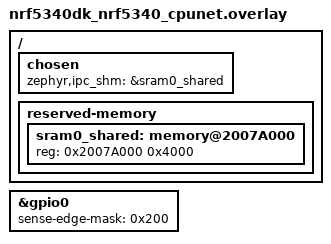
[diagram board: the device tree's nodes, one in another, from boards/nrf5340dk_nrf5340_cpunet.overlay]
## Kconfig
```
#
# Copyright (c) 2018 Nordic Semiconductor
#
# SPDX-License-Identifier: LicenseRef-BSD-5-Clause-Nordic
#

source "Kconfig.zephyr"

menu "Nordic UART BLE GATT service sample"

config BT_NUS_THREAD_STACK_SIZE
	int "Thread stack size"
	default 1024
	help
	  Stack size used in each of the two threads

config BT_NUS_UART_BUFFER_SIZE
	int "UART payload buffer element size"
	default 40
	help
	  Size of the payload buffer in each RX and TX FIFO element

config BT_NUS_SECURITY_ENABLED
	bool "Enable security"
	default y
	select BT_SMP
	help
	  "Enable BLE security for the UART service"

config BT_NUS_UART_RX_WAIT_TIME
	int "Timeout for UART RX complete event"
	default 50
	help
	  Wait for RX complete event time in milliseconds

endmenu

menu "nRF53 BLE custom"

config RPC_REMOTE_API
	bool "app core and net core communicate by remote API. that is, app core can call net core API, and net core can also call app core API"
	help
	  enable the RPC api mode
	
config RPC_SMP_BT
	bool "load DFU example over BLE SMP"
	help
		if yes, load DFU example over BLE SMP

endmenu	  
```

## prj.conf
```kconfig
#
# Copyright (c) 2018 Nordic Semiconductor
#
# SPDX-License-Identifier: LicenseRef-BSD-5-Clause-Nordic
#

## Open the config if you want to debug netcore ##
# CONFIG_NULL_POINTER_EXCEPTION_DETECTION_NONE=y

# Config logger
CONFIG_LOG=y
CONFIG_LOG_PRINTK=y
CONFIG_ASSERT=y
# CONFIG_LOG_BUFFER_SIZE=4096

# ## disable logging ##
# CONFIG_LOG=n
# CONFIG_USE_SEGGER_RTT=n
# CONFIG_SERIAL=n
# CONFIG_ASSERT=n
# CONFIG_PRINTK=n

# CONFIG_PRINTK=y
# CONFIG_SERIAL=y

# CONFIG_HEAP_MEM_POOL_SIZE=4096
# CONFIG_SYSTEM_WORKQUEUE_STACK_SIZE=4096

## nrf_rpc configurations ##
CONFIG_RPC_REMOTE_API=y
CONFIG_NRF_RPC=y
CONFIG_NRF_RPC_CBOR=y
CONFIG_NRF_RPC_THREAD_STACK_SIZE=4096

## Open the following config to run SMP OTA ##
CONFIG_RPC_SMP_BT=y
CONFIG_MCUMGR_SMP_BT_AUTHEN=n
# CONFIG_MCUMGR_SMP_REASSEMBLY_BT=y
# CONFIG_MCUMGR_SMP_BT_CONN_PARAM_CONTROL=y

## BT configurations ##
CONFIG_BT=y
CONFIG_BT_PERIPHERAL=y
CONFIG_BT_DEVICE_NAME="comprehensive_rpc"
#limited by RPMSG_BUFFER_SIZE
CONFIG_BT_L2CAP_TX_MTU=396
CONFIG_BT_BUF_ACL_RX_SIZE=400
CONFIG_BT_BUF_ACL_TX_SIZE=400
CONFIG_BT_CTLR_DATA_LENGTH_MAX=251
CONFIG_BT_PERIPHERAL_PREF_MIN_INT=6
CONFIG_BT_PERIPHERAL_PREF_MAX_INT=9
CONFIG_BT_GATT_DYNAMIC_DB=y
CONFIG_BT_RX_STACK_SIZE=4096

# Enable the NUS service
CONFIG_BT_NUS=y

## Enable bonding ##
# CONFIG_BT_SETTINGS=y
# CONFIG_BT_L2CAP_DYNAMIC_CHANNEL=y
# CONFIG_BT_SETTINGS_CCC_STORE_ON_WRITE=y
# CONFIG_BT_NUS_SECURITY_ENABLED=y
# CONFIG_BT_SMP_ALLOW_UNAUTH_OVERWRITE=y
# # CONFIG_BT_USE_DEBUG_KEYS=y
# # CONFIG_BT_STORE_DEBUG_KEYS=y

## Open the following config to run nrf_dfu OTA ##
# CONFIG_NRF_DFU_BT=y
# CONFIG_NRF_DFU_RPC_NET=y

## Enable bonding ##
CONFIG_BT_NUS_SECURITY_ENABLED=n
# CONFIG_BT_SETTINGS=y
# CONFIG_FLASH=y
# CONFIG_FLASH_PAGE_LAYOUT=y
# CONFIG_FLASH_MAP=y
# CONFIG_NVS=y
# # CONFIG_SETTINGS_NVS_SECTOR_COUNT=2
# CONFIG_PM_PARTITION_SIZE_SETTINGS_STORAGE=0x1000
# CONFIG_SETTINGS=y
# CONFIG_BT_SMP_ALLOW_UNAUTH_OVERWRITE=y
CONFIG_BT_LL_SW_SPLIT=y
```

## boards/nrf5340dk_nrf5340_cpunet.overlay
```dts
/delete-node/ &sram0_shared;

/ {
	chosen {
		/* shared memory reserved for the inter-processor communication */
		zephyr,ipc_shm = &sram0_shared;
	};

	reserved-memory {
		#address-cells = <1>;
		#size-cells = <1>;
		ranges;	
		sram0_shared: memory@2007A000 {
			/* SRAM allocated to shared memory */
			reg = <0x2007A000 0x4000>;
		};
	};
};

&gpio0 {
	/* button4 -> P0.9 sense for edge */
	sense-edge-mask = <0x200>;
};
```

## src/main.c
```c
/*
 * Copyright (c) 2018 Nordic Semiconductor ASA
 *
 * SPDX-License-Identifier: LicenseRef-BSD-5-Clause-Nordic
 */

/** @file
 *  @brief Nordic UART Bridge Service (NUS) sample
 */

#include <zephyr/types.h>
#include <zephyr/kernel.h>
#include <zephyr/drivers/uart.h>
#include <zephyr/device.h>
#include <soc.h>
#include <zephyr/bluetooth/bluetooth.h>
#include <zephyr/bluetooth/uuid.h>
#include <zephyr/bluetooth/gatt.h>
#include <zephyr/bluetooth/hci.h>
#include <bluetooth/services/nus.h>
#include <zephyr/settings/settings.h>
#include <stdio.h>
#include <zephyr/logging/log.h>
#include "rpc_net_api.h"
#include <zephyr/drivers/gpio.h>

#ifdef CONFIG_RPC_SMP_BT
#include "rpc_net_smp_bt.h"
#endif

#define LOG_MODULE_NAME main
LOG_MODULE_REGISTER(LOG_MODULE_NAME);

#define STACKSIZE CONFIG_BT_NUS_THREAD_STACK_SIZE
#define PRIORITY 7

#define DEVICE_NAME CONFIG_BT_DEVICE_NAME
#define DEVICE_NAME_LEN	(sizeof(DEVICE_NAME) - 1)

#define KEY_PASSKEY_ACCEPT DK_BTN1_MSK
#define KEY_PASSKEY_REJECT DK_BTN2_MSK


static K_SEM_DEFINE(ble_conn_ok, 0, 1);

struct bt_conn *current_conn;
// static struct bt_conn *auth_conn;

static const struct bt_data ad[] = {
	BT_DATA_BYTES(BT_DATA_FLAGS, (BT_LE_AD_GENERAL | BT_LE_AD_NO_BREDR)),
	BT_DATA(BT_DATA_NAME_COMPLETE, DEVICE_NAME, DEVICE_NAME_LEN),
};

/*
static const struct bt_data sd[] = {
	BT_DATA_BYTES(BT_DATA_UUID128_ALL, BT_UUID_NUS_VAL),
};
*/


K_SEM_DEFINE(sem_nus_op, 0, 1);

const struct device *gpio_dev;
#define EXT_INT_IO	9  //p0.09
#define EXT_INT_CONF	(GPIO_INPUT | GPIO_PULL_UP)
static struct gpio_callback ext_int_cb_data;

#ifdef CONFIG_BT_GATT_CLIENT
static struct bt_gatt_exchange_params exchange_params;

static void exchange_func(struct bt_conn *conn, uint8_t att_err,
			  struct bt_gatt_exchange_params *params)
{
	if (att_err)
	{
		LOG_ERR("MTU exchange failed");
	}
	else
	{
		LOG_INF("MTU updated to %d", bt_gatt_get_mtu(conn)); 
	}
	
}
#endif

static void connected(struct bt_conn *conn, uint8_t err)
{
	char addr[BT_ADDR_LE_STR_LEN];	

	if (err) {
		LOG_ERR("Connection failed (err %u)", err);
		return;
	}

	bt_addr_le_to_str(bt_conn_get_dst(conn), addr, sizeof(addr));
	LOG_INF("Connected %s", (addr));

	current_conn = bt_conn_ref(conn);

	k_sem_give(&ble_conn_ok);

#ifdef CONFIG_BT_NUS_SECURITY_ENABLED
	if (bt_conn_set_security(conn, BT_SECURITY_L2)) {
		printk("Failed to set security\n");
	}	
#endif

#ifdef CONFIG_RPC_REMOTE_API
	err = net2app_send_conn_status(1);
	if (err) {
		LOG_ERR("send connected err %d", err);
	}	
#endif

#ifdef CONFIG_BT_GATT_CLIENT		
	exchange_params.func = exchange_func;
	err = bt_gatt_exchange_mtu(conn, &exchange_params);
	if (err) {
		LOG_ERR("MTU exchange failed");
	} 		
#endif
	
}

static void disconnected(struct bt_conn *conn, uint8_t reason)
{
	char addr[BT_ADDR_LE_STR_LEN];

	bt_addr_le_to_str(bt_conn_get_dst(conn), addr, sizeof(addr));

	LOG_INF("Disconnected: %s (reason %u)", (addr), reason);

	if (current_conn) {
		bt_conn_unref(current_conn);
		current_conn = NULL;		
	}

#ifdef CONFIG_RPC_REMOTE_API
	int err = net2app_send_conn_status(0);
	if (err) {
		LOG_ERR("send disconnected err %d", err);
	}	
#endif

}

#ifdef CONFIG_BT_NUS_SECURITY_ENABLED
static void security_changed(struct bt_conn *conn, bt_security_t level,
			     enum bt_security_err err)
{
	char addr[BT_ADDR_LE_STR_LEN];

	bt_addr_le_to_str(bt_conn_get_dst(conn), addr, sizeof(addr));

	if (!err) {
		LOG_INF("Security changed: %s level %u", (addr),
			level);
	} else {
		LOG_WRN("Security failed: %s level %u err %d", (addr),
			level, err);
	}
}
#endif

static struct bt_conn_cb conn_callbacks = {
	.connected    = connected,
	.disconnected = disconnected,
#ifdef CONFIG_BT_NUS_SECURITY_ENABLED
	.security_changed = security_changed,
#endif	
};


static void bt_nus_receive_cb(struct bt_conn *conn, const uint8_t *const data,
			  uint16_t len)
{	
	char addr[BT_ADDR_LE_STR_LEN] = {0};
	int err;	

	bt_addr_le_to_str(bt_conn_get_dst(conn), addr, ARRAY_SIZE(addr));

	LOG_INF("Received data from: %s", (addr));
	LOG_HEXDUMP_INF(data, len, "data:");

#ifdef CONFIG_RPC_REMOTE_API	
	err = net2app_send_nus((uint8_t *)data, len);
	if (err) {
		LOG_ERR("network to application core nus send err %d", err);
	}	
#endif

}

static struct bt_nus_cb nus_cb = {
	.received = bt_nus_receive_cb,
};

void ext_int_isr(const struct device *dev, struct gpio_callback *cb,
		    uint32_t pins)
{	
	LOG_INF("button4 pressed and going to send nus packet\n");
    k_sem_give(&sem_nus_op);    
}

void setup_ext_int(void)
{
	int err;

	gpio_dev = device_get_binding(DT_NODE_FULL_NAME(DT_NODELABEL(gpio0)));
	if (gpio_dev == NULL) {
		printk("GPIO_0 bind error");
		return;
	}
	err = gpio_pin_configure(gpio_dev, EXT_INT_IO,
				EXT_INT_CONF);
	if (err) {
		printk("GPIO_0 config error: %d", err);
		return;
	}

	err = gpio_pin_interrupt_configure(gpio_dev, EXT_INT_IO,
					   GPIO_INT_EDGE_FALLING);
	if (err) {
		printk("GPIO_0 enable callback error: %d", err);
	}

	gpio_init_callback(&ext_int_cb_data, ext_int_isr,
			BIT(EXT_INT_IO));
	err = gpio_add_callback(gpio_dev, &ext_int_cb_data);
	if (err) {
		printk("GPIO_0 add callback error: %d", err);
		return;
	}
}

#if defined(CONFIG_BT_NUS_SECURITY_ENABLED)
static void auth_passkey_display(struct bt_conn *conn, unsigned int passkey)
{
	char addr[BT_ADDR_LE_STR_LEN];

	bt_addr_le_to_str(bt_conn_get_dst(conn), addr, sizeof(addr));

	LOG_INF("Passkey for %s: %06u", (addr), passkey);
}

static void auth_passkey_confirm(struct bt_conn *conn, unsigned int passkey)
{
	char addr[BT_ADDR_LE_STR_LEN];

	// auth_conn = bt_conn_ref(conn);

	bt_addr_le_to_str(bt_conn_get_dst(conn), addr, sizeof(addr));

	LOG_INF("Passkey for %s: %06u", (addr), passkey);
	LOG_INF("Press Button 1 to confirm, Button 2 to reject.");
}


static void auth_cancel(struct bt_conn *conn)
{
	char addr[BT_ADDR_LE_STR_LEN];

	bt_addr_le_to_str(bt_conn_get_dst(conn), addr, sizeof(addr));

	LOG_INF("Pairing cancelled: %s", (addr));
}


static void pairing_complete(struct bt_conn *conn, bool bonded)
{
	char addr[BT_ADDR_LE_STR_LEN];

	bt_addr_le_to_str(bt_conn_get_dst(conn), addr, sizeof(addr));

	LOG_INF("Pairing completed: %s, bonded: %d", (addr),
		bonded);
}


static void pairing_failed(struct bt_conn *conn, enum bt_security_err reason)
{
	char addr[BT_ADDR_LE_STR_LEN];

	bt_addr_le_to_str(bt_conn_get_dst(conn), addr, sizeof(addr));

	LOG_INF("Pairing failed conn: %s, reason %d", (addr),
		reason);
}


static struct bt_conn_auth_cb conn_auth_callbacks = {
	.passkey_display = NULL, //auth_passkey_display,
	.passkey_confirm = NULL, //auth_passkey_confirm,
	.cancel = NULL, //auth_cancel,	
	.pairing_complete = pairing_complete,
	.pairing_failed = pairing_failed
};
#endif


void main(void)
{
	
	int err = 0;
	
	printk("### netcore firmware compiled at %s %s\n", __TIME__, __DATE__);
	
	setup_ext_int();
	
	bt_conn_cb_register(&conn_callbacks);

#ifdef 	CONFIG_BT_NUS_SECURITY_ENABLED
	bt_conn_auth_cb_register(&conn_auth_callbacks);		
#endif	

	err = bt_enable(NULL);
	if (err) {
		printk("bt enable error %d\n", err);		
		return;
	}
	
#ifdef CONFIG_RPC_SMP_BT
	/* Initialize the Bluetooth mcumgr transport. */
	smp_bt_register_rpc();
#endif

	LOG_INF("Bluetooth initialized");	

	if (IS_ENABLED(CONFIG_SETTINGS)) {
		settings_load();
	}

	err = bt_nus_init(&nus_cb);
	if (err) {
		LOG_ERR("Failed to initialize UART service (err: %d)", err);
		return;
	}

	err = bt_le_adv_start(BT_LE_ADV_CONN, ad, ARRAY_SIZE(ad), NULL,
			      0);
	if (err) {
		LOG_ERR("Advertising failed to start (err %d)", err);
	}

	printk("Started NUS example on netcore\n");
	
#ifdef CONFIG_RPC_REMOTE_API
	err = net2app_send_bt_addr();
	if (err) {
		LOG_ERR("BT dev addr sent err %d", err);
	}
#endif		

	for (;;) {		
		k_sleep(K_SECONDS(5));
		printk("netcore main\r");	
	}
}

void ble_write_thread(void)
{
	static char data[20];
	static uint8_t cnt;
	int err;

	/* Don't go any further until BLE is initialized */
	k_sem_take(&ble_conn_ok, K_FOREVER);
	cnt = 0;

	for (;;) {
		k_sem_take(&sem_nus_op, K_FOREVER);		
		snprintf(data, 12, "HelloNet%d", cnt++);		
		data[11] = 0;		
		err = bt_nus_send(NULL, data, 12);
		if (err) {
			LOG_WRN("bt_nus_send err %d", err);
		}
	
	}
}

K_THREAD_DEFINE(ble_write_thread_id, STACKSIZE, ble_write_thread, NULL, NULL,
		NULL, PRIORITY, 0, 0);
```

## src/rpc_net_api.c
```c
/*
 * Copyright (c) 2020 Nordic Semiconductor ASA
 *
 * SPDX-License-Identifier: LicenseRef-BSD-5-Clause-Nordic
 */

#include <zephyr/kernel.h>
#include <zephyr/device.h>
#include <zephyr/devicetree.h>
#include <zephyr/drivers/gpio.h>
#include <stdio.h>
#include "rpc_net_api.h"
#include "nrf_rpc_tr.h"
#include <zephyr/logging/log.h>
#include <zephyr/drivers/uart.h>
#include "common_ids.h"
#include <zephyr/bluetooth/bluetooth.h>
#include <zephyr/bluetooth/hci.h>

#define LOG_MODULE_NAME rpc_net_example
LOG_MODULE_REGISTER(LOG_MODULE_NAME);


int net2app_send_bt_addr(void)
{

	bt_addr_le_t addrs[CONFIG_BT_ID_MAX];
	size_t count = ARRAY_SIZE(addrs);
	char addr_s[BT_ADDR_LE_STR_LEN];

	bt_id_get(addrs, &count);

	bt_addr_le_to_str(&addrs[0], addr_s, sizeof(addr_s));

	printk("===BT dev addr: %s ====\n", addr_s);

	return rpc_net2app_send(NET2APP_BT_ADDR_SEND, (uint8_t *)&addrs[0], 7);
	 
}

int net2app_send_nus(uint8_t *data, uint16_t len)
{
	return rpc_net2app_send(NET2APP_BT_NUS_RECV, data, len);
}

int net2app_send_conn_status(uint8_t connected)
{
	return rpc_net2app_send(NET2APP_BT_CONN_STATUS, (uint8_t *)&connected, 1);
}
```

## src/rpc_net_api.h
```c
/*
 * Copyright (c) 2020 Nordic Semiconductor ASA
 *
 * SPDX-License-Identifier: Apache-2.0
 */

#ifndef RPC_NET_API_H_
#define RPC_NET_API_H_

#include <zephyr/types.h>


/**
 * @file
 * @defgroup entropy_ser Entropy driver serialization
 * @{
 * @brief Entropy serialization API.
 */

#ifdef __cplusplus
extern "C" {
#endif

int net2app_send_bt_addr(void);
int net2app_send_nus(uint8_t *data, uint16_t len);
int net2app_send_conn_status(uint8_t connected);

int rpc_net2app_send(int type, uint8_t *buffer, size_t length);

#ifdef __cplusplus
}
#endif

/**
 * @}
 */

#endif /* RPC_NET_API_H_ */
```

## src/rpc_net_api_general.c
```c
/*
 * Copyright (c) 2020 Nordic Semiconductor ASA
 *
 * SPDX-License-Identifier: LicenseRef-BSD-5-Clause-Nordic
 */
#include <errno.h>
#include <zephyr/init.h>
#include <string.h>
#include <nrf_rpc/nrf_rpc_ipc.h>
#include <nrf_rpc_cbor.h>
#include <zcbor_common.h>
#include <zcbor_decode.h>
#include <zcbor_encode.h>
#include "common_ids.h"
#include "rpc_net_api.h"
#include <bluetooth/services/nus.h>
#include <zephyr/logging/log.h>

#define LOG_MODULE_NAME rpc_net_api
LOG_MODULE_REGISTER(LOG_MODULE_NAME);

#define CBOR_BUF_SIZE 16

NRF_RPC_IPC_TRANSPORT(rpc_api_tr, DEVICE_DT_GET(DT_NODELABEL(ipc0)), "nrf_rpc_ept_2");
NRF_RPC_GROUP_DEFINE(rpc_api, "RPC_API", &rpc_api_tr, NULL, NULL, NULL);

static void rsp_error_code_send(const struct nrf_rpc_group *group, int err_code)
{
	struct nrf_rpc_cbor_ctx ctx;

	NRF_RPC_CBOR_ALLOC(group, ctx, CBOR_BUF_SIZE);
	zcbor_int32_put(ctx.zs, err_code);

	nrf_rpc_cbor_rsp_no_err(group, &ctx);
}

static void rpc_app2net_send(const struct nrf_rpc_group *group, struct nrf_rpc_cbor_ctx *ctx, void *handler_data)
{
	struct zcbor_string zst;
	int err = -NRF_EINVAL;
	size_t length;
	uint8_t buf[256];
	int type;

	if (!zcbor_int32_decode(ctx->zs, &type)) {
		goto cbor_error_exit;
	}

	if (!zcbor_int32_decode(ctx->zs, &length) || length > ARRAY_SIZE(buf)) {
		goto cbor_error_exit;
	}
	
	if (!zcbor_bstr_decode(ctx->zs, &zst) || zst.len > ARRAY_SIZE(buf)) {
		goto cbor_error_exit;
	}
	length = zst.len;
	memcpy(buf, zst.value, zst.len);

	switch (type)
	{
		case APP2NET_BT_NUS_SEND:
			LOG_HEXDUMP_INF(buf, length, "nus data to send:");
			err = bt_nus_send(NULL, buf, length);
			break;
		default:
			break;
	}

cbor_error_exit:
	nrf_rpc_cbor_decoding_done(group, ctx);
	rsp_error_code_send(group, err);
}

NRF_RPC_CBOR_CMD_DECODER(rpc_api, rpc_app2net_send_name,
			 RPC_COMMAND_APP_SEND,
			 rpc_app2net_send, NULL);

static void rsp_error_code_handle(const struct nrf_rpc_group *group, struct nrf_rpc_cbor_ctx *ctx, void *handler_data)
{
	int32_t val;

	if (zcbor_int32_decode(ctx->zs, &val)) {
		*(int *)handler_data = (int)val;
	} else {
		*(int *)handler_data = -NRF_EINVAL;
	}
}

int rpc_net2app_send(int type, uint8_t *buffer, size_t length)
{
	int err;
	int result;
	struct nrf_rpc_cbor_ctx ctx;

	if (!buffer || length < 1) {
		return -NRF_EINVAL;
	}	

	NRF_RPC_CBOR_ALLOC(&rpc_api, ctx, CBOR_BUF_SIZE + length);
	zcbor_int32_put(ctx.zs, type);
	zcbor_int32_put(ctx.zs, length);
	zcbor_bstr_encode_ptr(ctx.zs, buffer, length);	

	err = nrf_rpc_cbor_cmd(&rpc_api, RPC_COMMAND_NET_SEND, &ctx,
			       rsp_error_code_handle, &result);
	if (err) {
		return err;
	}

	return result;
}


static void err_handler(const struct nrf_rpc_err_report *report)
{
	printk("nRF RPC error %d ocurred. See nRF RPC logs for more details.",
	       report->code);
	k_oops();
}


static int serialization_init(const struct device *dev)
{
	ARG_UNUSED(dev);

	int err;

	printk("Init begin\n");

	err = nrf_rpc_init(err_handler);
	if (err) {
		return -NRF_EINVAL;
	}

	printk("Init done\n");

	return 0;
}


SYS_INIT(serialization_init, POST_KERNEL, CONFIG_APPLICATION_INIT_PRIORITY);
```

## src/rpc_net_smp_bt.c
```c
/*
 * Copyright (c) 2020 Nordic Semiconductor ASA
 *
 * SPDX-License-Identifier: LicenseRef-BSD-5-Clause-Nordic
 */

/** @file
 * @brief Bluetooth transport for the mcumgr SMP protocol.
 */

#include <errno.h>
#include <zephyr/kernel.h>
#include <zephyr/init.h>
#include <zephyr/bluetooth/bluetooth.h>
#include <zephyr/bluetooth/uuid.h>
#include <zephyr/bluetooth/gatt.h>
#include <string.h>
#include <nrf_rpc/nrf_rpc_ipc.h>
#include <nrf_rpc_cbor.h>
#include <zcbor_common.h>
#include <zcbor_decode.h>
#include <zcbor_encode.h>
#include "common_ids.h"
#include <zephyr/logging/log.h>

LOG_MODULE_REGISTER(rpc_smp_bt, 3);

extern struct bt_conn *current_conn;

/* SMP service.
 * {8D53DC1D-1DB7-4CD3-868B-8A527460AA84}
 */
static struct bt_uuid_128 smp_bt_svc_uuid = BT_UUID_INIT_128(
	0x84, 0xaa, 0x60, 0x74, 0x52, 0x8a, 0x8b, 0x86,
	0xd3, 0x4c, 0xb7, 0x1d, 0x1d, 0xdc, 0x53, 0x8d);

/* SMP characteristic; used for both requests and responses.
 * {DA2E7828-FBCE-4E01-AE9E-261174997C48}
 */
static struct bt_uuid_128 smp_bt_chr_uuid = BT_UUID_INIT_128(
	0x48, 0x7c, 0x99, 0x74, 0x11, 0x26, 0x9e, 0xae,
	0x01, 0x4e, 0xce, 0xfb, 0x28, 0x78, 0x2e, 0xda);

#define CBOR_BUF_SIZE 16

NRF_RPC_IPC_TRANSPORT(rpc_smp_tr, DEVICE_DT_GET(DT_NODELABEL(ipc0)), "nrf_rpc_ept_1");
NRF_RPC_GROUP_DEFINE(rpc_smp, "RPC_SMP", &rpc_smp_tr, NULL, NULL, NULL);

static void rsp_error_code_send(const struct nrf_rpc_group *group, int err_code)
{
	struct nrf_rpc_cbor_ctx ctx;

	NRF_RPC_CBOR_ALLOC(group, ctx, CBOR_BUF_SIZE);

	zcbor_int32_put(ctx.zs, err_code);

	nrf_rpc_cbor_rsp_no_err(group, &ctx);
}

static void rsp_error_code_handle(const struct nrf_rpc_group *group,
				       struct nrf_rpc_cbor_ctx *ctx, void *handler_data)
{
	int32_t val;

	if (zcbor_int32_decode(ctx->zs, &val)) {
		*(int *)handler_data = (int)val;
	} else {
		*(int *)handler_data = -NRF_EINVAL;
	}
}

int rpc_net_bt_smp_receive_cb(const uint8_t *buffer, uint16_t length)
{
	int err;
	int result;
	struct nrf_rpc_cbor_ctx ctx;

	if (!buffer || length < 1) {
		LOG_ERR("net rpc rx len error");
		return -NRF_EINVAL;
	}	
	printk("smp rec len %x\r", length);
	NRF_RPC_CBOR_ALLOC(&rpc_smp, ctx, CBOR_BUF_SIZE + length);
	zcbor_bstr_encode_ptr(ctx.zs, buffer, length);
	
	err = nrf_rpc_cbor_cmd(&rpc_smp, RPC_COMMAND_NET_BT_SMP_RECEIVE_CB, &ctx,
			       rsp_error_code_handle, &result);
	if (err) {
		LOG_ERR("net rpc cbor cmd err %d", err);
		return err;
	}

	return result;
}

/**
 * Write handler for the SMP characteristic; processes an incoming SMP request.
 */
static ssize_t smp_bt_chr_write(struct bt_conn *conn,
				const struct bt_gatt_attr *attr,
				const void *buf, uint16_t len, uint16_t offset,
				uint8_t flags)
{
	LOG_HEXDUMP_DBG(buf, len, "rpc smp bt rx:");
	rpc_net_bt_smp_receive_cb(buf, len);
	return len;
}

static void smp_bt_ccc_changed(const struct bt_gatt_attr *attr, uint16_t value)
{
}

static struct bt_gatt_attr smp_bt_attrs[] = {
	/* SMP Primary Service Declaration */
	BT_GATT_PRIMARY_SERVICE(&smp_bt_svc_uuid),

	BT_GATT_CHARACTERISTIC(&smp_bt_chr_uuid.uuid,
			       BT_GATT_CHRC_WRITE_WITHOUT_RESP |
			       BT_GATT_CHRC_NOTIFY,
#ifdef CONFIG_MCUMGR_SMP_BT_AUTHEN
			       BT_GATT_PERM_WRITE_AUTHEN,
#else
			       BT_GATT_PERM_WRITE,
#endif
			       NULL, smp_bt_chr_write, NULL),
	BT_GATT_CCC(smp_bt_ccc_changed,
#ifdef CONFIG_MCUMGR_SMP_BT_AUTHEN
			       BT_GATT_PERM_READ_AUTHEN |
			       BT_GATT_PERM_WRITE_AUTHEN),
#else
			       BT_GATT_PERM_READ | BT_GATT_PERM_WRITE),
#endif
};

static struct bt_gatt_service smp_bt_svc = BT_GATT_SERVICE(smp_bt_attrs);

/**
 * Transmits an SMP response over the specified Bluetooth connection.
 */
static void rpc_net_bt_smp_send(const struct nrf_rpc_group *group,
				       struct nrf_rpc_cbor_ctx *ctx, void *handler_data)
{
	struct zcbor_string zst;
	int err;

#ifdef CONFIG_BT_L2CAP_TX_MTU	
	uint8_t buf[CONFIG_BT_L2CAP_TX_MTU];
#else
	uint8_t buf[256];
#endif

	if (!zcbor_bstr_decode(ctx->zs, &zst) || zst.len > sizeof(buf)) {
		LOG_ERR("net rpc send len err %d", zst.len);
		err = -EBADMSG;
	}
	else
	{
		memcpy(buf, zst.value, zst.len);
		LOG_HEXDUMP_DBG(buf, zst.len, "rpc smp bt tx rsp:");
		err = bt_gatt_notify(current_conn, smp_bt_attrs + 2, buf, zst.len);		
	}
	
	nrf_rpc_cbor_decoding_done(group, ctx);

	rsp_error_code_send(group, err);

}

NRF_RPC_CBOR_CMD_DECODER(rpc_smp, rpc_net_bt_smp_send_xx,
			 RPC_COMMAND_APP_BT_SMP_SEND,
			 rpc_net_bt_smp_send, NULL);

static void rpc_net_bt_smp_get_mtu(const struct nrf_rpc_group *group,
				       struct nrf_rpc_cbor_ctx *ctx, void *handler_data)
{
	uint16_t mtu;

	nrf_rpc_cbor_decoding_done(group, ctx);

	mtu = bt_gatt_get_mtu(current_conn) - 3;
	LOG_INF("smp MTU:%d", mtu);

	rsp_error_code_send(group, mtu);
}

NRF_RPC_CBOR_CMD_DECODER(rpc_smp, rpc_net_bt_smp_get_mtu_name,
			 RPC_COMMAND_APP_BT_SMP_GET_MTU,
			 rpc_net_bt_smp_get_mtu, NULL);

int smp_bt_register_rpc(void)
{
	printk("register smp bt\r");
	return bt_gatt_service_register(&smp_bt_svc);
}

int smp_bt_unregister_rpc(void)
{
	return bt_gatt_service_unregister(&smp_bt_svc);
}
```
